# PIC18LF4620 register map
Vendor: Microchip
Registers are 8-bit, read-write, no defined reset value unless marked. A register's access mark holds for its fields unless they carry their own. Addresses are absolute, and some are shared; only a register's first bit layout is shown; [hi:lo] are bit positions.

## CONFIG — Configuration words, addresses in ProgramSpace
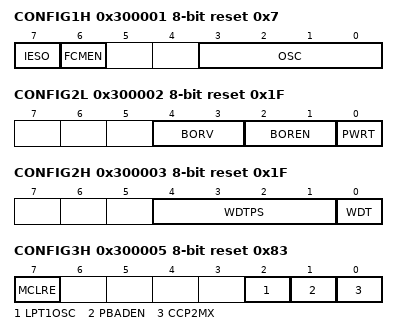
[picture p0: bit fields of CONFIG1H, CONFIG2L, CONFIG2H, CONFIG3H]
0x300001 CONFIG1H reset 0x7
  [7] IESO — Internal/External Oscillator Switchover bit
    1=ON (Oscillator Switchover mode enabled); 0=OFF (Oscillator Switchover mode disabled)
  [6] FCMEN — Fail-Safe Clock Monitor Enable bit
    1=ON (Fail-Safe Clock Monitor enabled); 0=OFF (Fail-Safe Clock Monitor disabled)
  [3:0] OSC — Oscillator Selection bits
    0b11xx=11XX External RC oscillator, CLKOUT function on RA6; 0b101x=101X External RC oscillator, CLKOUT function on RA6; 9=INTIO7 (Internal oscillator block, CLKOUT function on RA6, port function on RA7); 8=INTIO67 (Internal oscillator block, port function on RA6 and RA7); 7=RCIO6 (External RC oscillator, port function on RA6); 6=HSPLL (HS oscillator, PLL enabled (Clock Frequency = 4 x FOSC1)); 5=ECIO6 (EC oscillator, port function on RA6); 4=EC (EC oscillator, CLKOUT function on RA6); 3=RC (External RC oscillator, CLKO function on RA6); 2=HS (HS oscillator); 1=XT (XT oscillator); 0=LP (LP oscillator)
0x300002 CONFIG2L reset 0x1F
  [4:3] BORV — Brown Out Reset Voltage bits
    3=Minimum setting; 2=2; 1=1; 0=Maximum setting
  [2:1] BOREN — Brown-out Reset Enable bits
    3=SBORDIS (Brown-out Reset enabled in hardware only (SBOREN is disabled)); 2=NOSLP (Brown-out Reset enabled in hardware only and disabled in Sleep mode (SBOREN is disabled)); 1=ON (Brown-out Reset enabled and controlled by software (SBOREN is enabled)); 0=OFF (Brown-out Reset disabled in hardware and software)
  [0] PWRT — Power-up Timer Enable bit
    1=OFF (PWRT disabled); 0=ON (PWRT enabled)
0x300003 CONFIG2H reset 0x1F
  [4:1] WDTPS — Watchdog Timer Postscale Select bits
    15=1:32768; 14=1:16384; 13=1:8192; 12=1:4096; 11=1:2048; 10=1:1024; 9=1:512; 8=1:256; 7=1:128; 6=1:64; 5=1:32; 4=1:16; 3=1:8; 2=1:4; 1=1:2; 0=1:1
  [0] WDT — Watchdog Timer Enable bit
    1=ON (WDT enabled); 0=OFF (WDT disabled (control is placed on the SWDTEN bit))
0x300005 CONFIG3H reset 0x83
  [7] MCLRE — MCLR Pin Enable bit
    1=ON (MCLR pin enabled; RE3 input pin disabled); 0=OFF (RE3 input pin enabled; MCLR disabled)
  [2] LPT1OSC — Low-Power Timer1 Oscillator Enable bit
    1=ON (Timer1 configured for low-power operation); 0=OFF (Timer1 configured for higher power operation)
  [1] PBADEN — PORTB A/D Enable bit
    1=ON (PORTB<4:0> pins are configured as analog input channels on Reset); 0=OFF (PORTB<4:0> pins are configured as digital I/O on Reset)
  [0] CCP2MX — CCP2 MUX bit
    1=PORTC (CCP2 input/output is multiplexed with RC1); 0=PORTBE (CCP2 input/output is multiplexed with RB3)
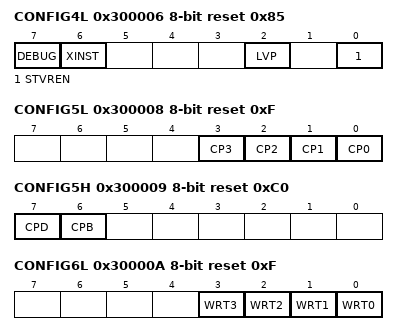
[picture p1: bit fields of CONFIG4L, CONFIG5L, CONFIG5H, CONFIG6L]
0x300006 CONFIG4L reset 0x85
  [7] DEBUG — Background Debugger Enable bit
    1=OFF (Background debugger disabled, RB6 and RB7 configured as general purpose I/O pins); 0=ON (Background debugger enabled, RB6 and RB7 are dedicated to In-Circuit Debug)
  [6] XINST — Extended Instruction Set Enable bit
    1=ON (Instruction set extension and Indexed Addressing mode enabled); 0=OFF (Instruction set extension and Indexed Addressing mode disabled (Legacy mode))
  [2] LVP — Single-Supply ICSP Enable bit
    1=ON (Single-Supply ICSP enabled); 0=OFF (Single-Supply ICSP disabled)
  [0] STVREN — Stack Full/Underflow Reset Enable bit
    1=ON (Stack full/underflow will cause Reset); 0=OFF (Stack full/underflow will not cause Reset)
0x300008 CONFIG5L reset 0xF
  [3] CP3 — Code Protection bit
    1=OFF (Block 3 (00C000-00FFFFh) not code-protected); 0=ON (Block 3 (00C000-00FFFFh) code-protected)
  [2] CP2 — Code Protection bit
    1=OFF (Block 2 (008000-00BFFFh) not code-protected); 0=ON (Block 2 (008000-00BFFFh) code-protected)
  [1] CP1 — Code Protection bit
    1=OFF (Block 1 (004000-007FFFh) not code-protected); 0=ON (Block 1 (004000-007FFFh) code-protected)
  [0] CP0 — Code Protection bit
    1=OFF (Block 0 (000800-003FFFh) not code-protected); 0=ON (Block 0 (000800-003FFFh) code-protected)
0x300009 CONFIG5H reset 0xC0
  [7] CPD — Data EEPROM Code Protection bit
    1=OFF (Data EEPROM not code-protected); 0=ON (Data EEPROM code-protected)
  [6] CPB — Boot Block Code Protection bit
    1=OFF (Boot block (000000-0007FFh) not code-protected); 0=ON (Boot block (000000-0007FFh) code-protected)
0x30000A CONFIG6L reset 0xF
  [3] WRT3 — Write Protection bit
    1=OFF (Block 3 (00C000-00FFFFh) not write-protected); 0=ON (Block 3 (00C000-00FFFFh) write-protected)
  [2] WRT2 — Write Protection bit
    1=OFF (Block 2 (008000-00BFFFh) not write-protected); 0=ON (Block 2 (008000-00BFFFh) write-protected)
  [1] WRT1 — Write Protection bit
    1=OFF (Block 1 (004000-007FFFh) not write-protected); 0=ON (Block 1 (004000-007FFFh) write-protected)
  [0] WRT0 — Write Protection bit
    1=OFF (Block 0 (000800-003FFFh) not write-protected); 0=ON (Block 0 (000800-003FFFh) write-protected)
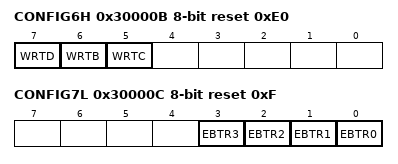
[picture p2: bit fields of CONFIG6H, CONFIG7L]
0x30000B CONFIG6H reset 0xE0
  [7] WRTD — Data EEPROM Write Protection bit
    1=OFF (Data EEPROM not write-protected); 0=ON (Data EEPROM write-protected)
  [6] WRTB — Boot Block Write Protection bit
    1=OFF (Boot Block (000000-0007FFh) not write-protected); 0=ON (Boot Block (000000-0007FFh) write-protected)
  [5] WRTC — Configuration Register Write Protection bit
    1=OFF (Configuration registers (300000-3000FFh) not write-protected); 0=ON (Configuration registers (300000-3000FFh) write-protected)
0x30000C CONFIG7L reset 0xF
  [3] EBTR3 — Table Read Protection bit
    1=OFF (Block 3 (00C000-00FFFFh) not protected from table reads executed in other blocks); 0=ON (Block 3 (00C000-00FFFFh) protected from table reads executed in other blocks)
  [2] EBTR2 — Table Read Protection bit
    1=OFF (Block 2 (008000-00BFFFh) not protected from table reads executed in other blocks); 0=ON (Block 2 (008000-00BFFFh) protected from table reads executed in other blocks)
  [1] EBTR1 — Table Read Protection bit
    1=OFF (Block 1 (004000-007FFFh) not protected from table reads executed in other blocks); 0=ON (Block 1 (004000-007FFFh) protected from table reads executed in other blocks)
  [0] EBTR0 — Table Read Protection bit
    1=OFF (Block 0 (000800-003FFFh) not protected from table reads executed in other blocks); 0=ON (Block 0 (000800-003FFFh) protected from table reads executed in other blocks)
0x30000D CONFIG7H reset 0x40
  [6] EBTRB — Boot Block Table Read Protection bit
    1=OFF (Boot Block (000000-0007FFh) not protected from table reads executed in other blocks); 0=ON (Boot Block (000000-0007FFh) protected from table reads executed in other blocks)
